# PIC32MZ0512EFF144 device description
Architecture: 32xxxx; Family: PIC32MZEF; Series: PIC32MZ
Registers are 32-bit, read-write, no defined reset value unless marked. A register's access mark holds for its fields unless they carry their own. Offsets are from the block's base; [hi:lo] are bit positions; {n}, {i} and the like mark numbered series; 'fields as' and 'values as' point back to an identical list.

## CMP
Instances: CMP 0x1f84c000 in periph_pb3_std
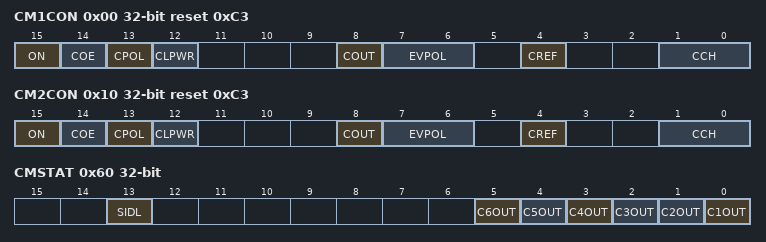
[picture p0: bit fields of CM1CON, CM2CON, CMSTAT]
0x00 CM1CON reset 0xC3 — Comparator Control Register
  [15] ON — Comparator ON bit
    1=Module is enabled. Setting this bit does not affect the other bits in this register; 0=Module is disabled and does not consume current. Clearing this bit does not affect the other bits in this register
  [14] COE — Comparator Output Enable bit
    1=Comparator output is driven on the output CxOUT pin; 0=Comparator output is not driven on the output CxOUT pin
  [13] CPOL — Comparator Output Inversion bit
    1=Output is inverted; 0=Output is not inverted
  [12] CLPWR
  [8] COUT — Comparator Output bit
    1=Output of the Comparator is a 1; 0=Output of the Comparator is a 0
  [7:6] EVPOL — Interrupt Event Polarity Select bits
    3=Comparator interrupt is generated on a low-to-high or high-to-low transition of the comparator output; 2=Comparator interrupt is generated on a high-to-low transition of the comparator output; 1=Comparator interrupt is generated on a low-to-high transition of the comparator output; 0=Comparator interrupt generation is disabled
  [4] CREF — Comparator Positive Input Configure bit
    1=Comparator non-inverting input is connected to the internal CVref; 0=Comparator non-inverting input is connected to the CxINA pin
  [1:0] CCH — Comparator Negative Input Select bits for Comparator
    3=Comparator inverting input is connected to the IVREF; 2=Comparator inverting input is connected to the CxIND pin; 1=Comparator inverting input is connected to the CxINC pin; 0=Comparator inverting input is connected to the CxINB pin
0x10 CM2CON reset 0xC3 — Comparator Control Register
  fields as CM1CON
0x60 CMSTAT — Comparator Status Register
  [13] SIDL — Stop in Idle Control bit
    1=All Comparator modules are disabled in Idle mode; 0=All Comparator modules continue to operate in the Idle mode
  [n-1] C{n}OUT (n=3..6)
  [1] C2OUT — Comparator Output bit
    1=Output of Comparator 2 is a 1; 0=Output of Comparator 2 is a 0
  [0] C1OUT — Comparator Output bit
    1=Output of Comparator 1 is a 1; 0=Output of Comparator 1 is a 0

## CVR
Instances: CVR 0x1f800e00 in periph_pb1_std
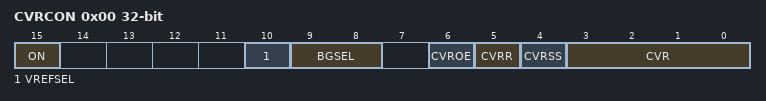
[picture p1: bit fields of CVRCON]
0x00 CVRCON — Comparator Voltage Reference Control Register
  [15] ON — Comparator Voltage Reference On bit
    1=Module is enabled. Setting this bit does not affect other bits in the register.; 0=Module is disabled and does not consume current. Clearing this bit does not affect the other bits in the register.
  [10] VREFSEL
  [9:8] BGSEL
  [6] CVROE — CVrefout Enable bit
    1=Voltage level is output on CVrefout pin; 0=Voltage level is disconnected from CVrefout pin
  [5] CVRR — CVref Range Selection bit
    1=0 to 0.67 CVrsrc; 0=0.25 CVrsrc to 0.75 CVrsrc
  [4] CVRSS — CVref Source Selection bit
    1=Comparator voltage reference source, CVRSRC = (VREF+) - (VREF-); 0=Comparator voltage reference source, CVRSRC = AVDD - AVSS
  [3:0] CVR

## DMT
Instances: DMT 0x1f800a00 in periph_pb1_std
0x00 DMTCON — Deadman Timer Control Register
  [15] ON — Deadman Timer Module Enable bit
    1=Deadman Timer module is enabled; 0=Deadman Timer module is disabled
0x10 DMTPRECLR — Deadman Timer Preclear Register
  [15:8] STEP1 — Preclear Enable bits
    64=Enables the Deadman Timer Preclear (Step 1)
0x20 DMTCLR — Deadman Timer Clear Register
  [7:0] STEP2 — Clear Timer bits
    8=Clears STEP1
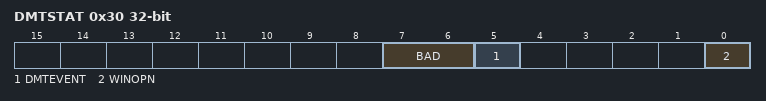
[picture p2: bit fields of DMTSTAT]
0x30 DMTSTAT ro — Deadman Timer Status Register
  [7:6] BAD
  [5] DMTEVENT — Deadman Timer Event bit
    1=Deadman timer event was detected (counter expired or bad STEP1 or STEP2 value was entered prior to counter increment); 0=Deadman timer even was not detected
  [0] WINOPN — Deadman Timer Clear Window bit
    1=Deadman timer clear window is open; 0=Deadman timer clear window is not open
0x40 DMTCNT ro — Deadman Timer Count Register
  [31:0] COUNTER
0x60 DMTPSCNT ro — Post Status Configure DMT Count Status Register
  [31:0] PSCNT
0x70 DMTPSINTV ro — Post Status Configure DMT Interval Status Register
  [31:0] PSINTV
Value list DMTSTAT__BAD2: 64=Incorrect STEP2 value was detected; 0=Incorrect STEP2 value was not detected
Value list DMTSTAT__BAD1: 128=Incorrect STEP1 value or out of sequence write to STEP2 was detected; 0=Incorrect STEP1 value was not detected
